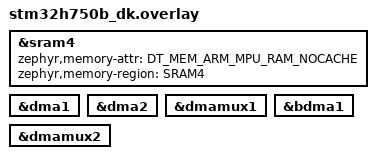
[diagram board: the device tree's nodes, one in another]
/*
 * Copyright (c) 2024 Abderrahmane JARMOUNI
 *
 * SPDX-License-Identifier: Apache-2.0
 */

&sram4 {
	zephyr,memory-attr = <DT_MEM_ARM_MPU_RAM_NOCACHE>;
	zephyr,memory-region = "SRAM4";
	status = "okay";
};

&dma1 {
	status = "okay";
};

&dma2 {
	status = "okay";
};

tst_dma0: &dmamux1 {
	status = "okay";
};

&bdma1 {
	status = "okay";
};

tst_dma1: &dmamux2 {
	status = "okay";
};
